# RN821X_RN721X_SOC_V2 register map
File version: v1.0.7
CPU: CM0 r0p0, little endian, no MPU, no FPU, 3 interrupt priority bits
Registers are 32-bit, read-write, reset 0x0 unless marked. A register's access mark holds for its fields unless they carry their own. Offsets are from the block's base; [hi:lo] are bit positions; {n}, {i} and the like mark numbered series; 'fields as' and 'values as' point back to an identical list.

## SYSCTL — system control
Base 0x40034000
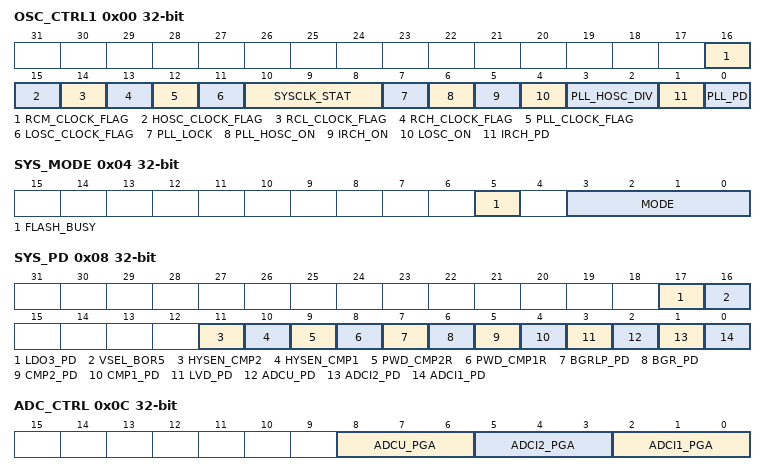
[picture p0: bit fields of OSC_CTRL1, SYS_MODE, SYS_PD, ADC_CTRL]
0x00 OSC_CTRL1 — system oscillator control register No.1
  [16] RCM_CLOCK_FLAG ro — RCM ON status flag
    0=OFF (clock off); 1=ON (clock on)
  [15] HOSC_CLOCK_FLAG ro — HOSC ON status flag
    0=OFF (clock off); 1=ON (clock on)
  [14] RCL_CLOCK_FLAG ro — internal RCL ON status flag
    0=OFF (clock off); 1=ON (clock on)
  [13] RCH_CLOCK_FLAG ro — internal RCH ON status flag
    0=OFF (clock off); 1=ON (clock on)
  [12] PLL_CLOCK_FLAG ro — PLL ON status flag
    0=OFF (clock off); 1=ON (clock on)
  [11] LOSC_CLOCK_FLAG ro — LOSC ON status flag
    0=OFF (clock off); 1=ON (clock on)
  [10:8] SYSCLK_STAT ro — system clock freq status flag
    0=7M4 (current system clock freq = 7.3728MHz); 1=3M6 (current system clock freq = 3.6864MHz); 2=1M8 (current system clock freq = 1.8432MHz); 3=32K (current system clock freq = 32.768KHz); 4=14M7 (current system clock freq = 14.7456Mhz); 5=29M5 (current system clock freq = 29.4912Mhz)
  [7] PLL_LOCK ro — PLL locked flag
    0=NUL (PLL hasn't locked yet); 1=LOCK (PLL locked)
  [6] PLL_HOSC_ON ro — system clock flag of external high-frequence oscillator or internal PLL
    0=NUL (PLL_HOSC isn't used as system clock); 1=SYS_CLK (PLL_HOSC used as system clock)
  [5] IRCH_ON ro — system clock flag of internal RC oscillator
    0=NUL (IRCH isn't used as system clock); 1=SYS_CLK (IRCH used as system clock)
  [4] LOSC_ON ro — system clock flag of losc or RCL
    0=NUL (losc isn't used as system clock); 1=SYS_CLK (losc used as system clock)
  [3:2] PLL_HOSC_DIV — system clock division(applicable for high frequency mode(PLL or HOSC))
    0=DIV1 (when PLL/HOSC selected as system clock not divided); 1=DIV2 (when PLL/HOSC selected as system clock divided by 2); 2=DIV4 (when PLL/HOSC selected as system clock divided by 4); 3=DIV8 (when PLL/HOSC selected as system clock divided by 8)
  [1] IRCH_PD — internal RCH oscillator disable bit (=1 disable, =0 enable)
    1=DIS (disable); 0=EN (enable)
  [0] PLL_PD — PLL disable bit (=1 disable, =0 enable)
    1=DIS (disable); 0=EN (enable)
0x04 SYS_MODE — system mode control register
  [5] FLASH_BUSY ro — FLASH busy status flag (=1 busy, =0 idle)
    0=IDLE; 1=BUSY (idle)
  [3:0] MODE — system clock configuration bits
    13=HCM (select HCM mode as system mode); 14=RCM (select RCM mode as system mode); 15=LCM (select LCM mode as system mode)
0x08 SYS_PD — system power-down control register
  [17] LDO3_PD — LDO3 power down switch bit(=1 power on, =0 power off)
    0=OFF (power off); 1=ON (power on)
  [16] VSEL_BOR5 — BOR5 voltage threshold bit
    0=HIGH (BOR5 high level(2.5/2.2V)); 1=LOW (BOR5 low level(2.1/1.8V))
  [11] HYSEN_CMP2 — CMP2 hysteresis switch bit
    1=ON (switch on); 0=OFF (switch off)
  [10] HYSEN_CMP1 — CMP1 hysteresis switch bit
    1=ON (switch on); 0=OFF (switch off)
  [9] PWD_CMP2R — switch bit of CMP2 internal simpling resistor(=1 register off, =0 register on)
    0=ON (switch on); 1=OFF (switch off)
  [8] PWD_CMP1R — switch bit of CMP1 internal simpling resistor(=1 register off, =0 register on)
    0=ON (switch on); 1=OFF (switch off)
  [7] BGRLP_PD — BGRLP power down switch bit(=1 power down, =0 power on)
    0=ON (power on); 1=OFF (power off)
  [6] BGR_PD — BGR power down switch bit(=1 power down, =0 power on)
    0=ON (power on); 1=OFF (power off)
  [5] CMP2_PD — power down switch bit of Comparator No.2 (=1 power down, =0 power on)
    0=ON (power on); 1=OFF (power off)
  [4] CMP1_PD — power down switch bit of Comparator No.1 (=1 power down, =0 power on)
    0=ON (power on); 1=OFF (power off)
  [3] LVD_PD — LVD power down switch bit(=1 power down, =0 power on)
    0=ON (power on); 1=OFF (power off)
  [2] ADCU_PD — U ADC power down switch bit(=1 power down, =0 power on)
    0=ON (power on); 1=OFF (power off)
  [1] ADCI2_PD — I2 ADC power down switch bit(=1 power down, =0 power on)
    0=ON (power on); 1=OFF (power off)
  [0] ADCI1_PD — I1 ADC power down switch bit(=1 power down, =0 power on)
    0=ON (power on); 1=OFF (power off)
0x0C ADC_CTRL — ADC control register
  [8:6] ADCU_PGA — ADC U PGA config bits
    0=1TIME (PGA config 1 time); 1=2TIME (PGA config 2 times); 2=4TIME (PGA config 4 times)
  [5:3] ADCI2_PGA — ADC I2 PGA config bits
    values as ADCU_PGA
  [2:0] ADCI1_PGA — ADC I1 PGA config bits
    0=1TIME (PGA config 1 time); 1=2TIME (PGA config 2 times); 2=8TIME (PGA config 8 times); 3=16TIME (PGA config 16 times)
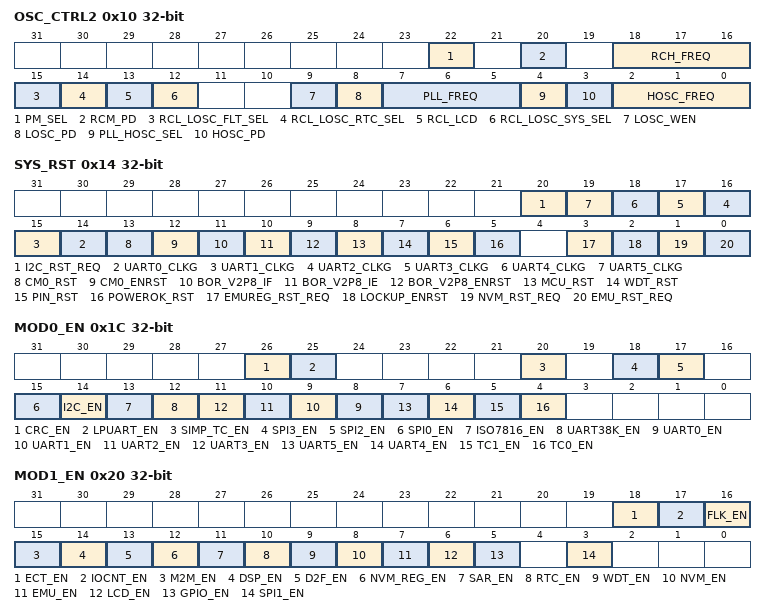
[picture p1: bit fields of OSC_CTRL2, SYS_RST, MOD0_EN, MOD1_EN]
0x10 OSC_CTRL2 — system oscillator control No.2
  [22] PM_SEL — EMU power mode selection bit
    0=NORM (select as normal mode); 1=NVM (select as NVM mode)
  [20] RCM_PD — internal RCM enable bit
    0=OFF (power off); 1=ON (power on)
  [18:16] RCH_FREQ — RCH frequency selection bits
    0=1M8 (internal RCH freq select 1.8432MHz); 1=3M6 (internal RCH freq select 3.6864MHz); 2=7M4 (internal RCH freq select 7.3728MHz); 3=14M7 (internal RCH freq select 14.7456Mhz); 4=29M5 (internal RCH freq select 29.4912Mhz)
  [15] RCL_LOSC_FLT_SEL — clock selection bit (RCL/LOSC) for KBI filter
    0=LOSC (select LOSC); 1=RCL (select RCL)
  [14] RCL_LOSC_RTC_SEL — clock selection bit (RCL/LOSC) for RTC
    0=LOSC (select LOSC); 1=RCL (select RCL)
  [13] RCL_LCD — clock selection bit (RCL/LOSC) for LCD
    0=LOSC (select LOSC); 1=RCL (select RCL)
  [12] RCL_LOSC_SYS_SEL — system clock selection bit for low frequency mode
    0=LOSC (select LOSC); 1=RCL (select RCL)
  [9] LOSC_WEN — LOSC_PD writable enable/disable bit
    0=DIS (LOSC_PD write disable); 1=EN (LOSC_PD write enable)
  [8] LOSC_PD — LOSC power down switch bit
    0=ON (power on); 1=OFF (power off)
  [7:5] PLL_FREQ — PLL freq selection bits
    0=7M4 (PLL freq select 7.3728MHz); 1=14M7 (PLL freq select 14.7456Mhz); 2=29M5 (PLL freq select 29.4912Mhz); 3=59M_DIV2 (PLL freq select 58.9824Mhz divided by 2)
  [4] PLL_HOSC_SEL — system clock selection bits for full speed mode
    0=PLL (select PLL as system clock); 1=HOSC (select HOSC as system clock)
  [3] HOSC_PD — HOSC disable bit (=1 disable HOSC, =0 enable HOSC)
    0=ON (power on); 1=OFF (power off)
  [2:0] HOSC_FREQ — freq of external high-frequence oscillator select bits
    0=7M4 (external high-frequence oscillator freq = 7.3728MHz); 1=14M7 (external high-frequence oscillator freq = 14.7456Mhz); 3=29M5_PLUS (external high-frequence oscillator freq = 29.4912Mhz (driver enhanced))
0x14 SYS_RST — system reset register
  [20] I2C_RST_REQ — I2C module soft reset cfg bit
    1=EN (enable module soft reset); 0=DIS (disable module soft reset)
  [n+14] UART{n}_CLKG (n=0..5) — UART{n} CM0 reset lock enable bit(during CM0 reset period lock transmission between CPU and UART)
  [13] CM0_RST write-1-clears — CM0 reset flag
    1=OCC (reset occured); 0=NUL (reset not occured)
  [12] CM0_ENRST — CM0 reset enable bit(do not reset EMU related module)
  [11] BOR_V2P8_IF write-1-clears — BOR 2.8V threshold interrupt flag
  [10] BOR_V2P8_IE — BOR 2.8V threshold interrupt enable bit
  [9] BOR_V2P8_ENRST — lower than BOR 2.8V threshold reset CPU cfg bit
  [8] MCU_RST write-1-clears — CPU reset flag(software or LOCKUP) (=1 reset occured)
    1=OCC (reset occured); 0=NUL (reset not occured)
  [7] WDT_RST write-1-clears — WDT reset flag (=1 reset occurd)
    1=OCC (reset occured); 0=NUL (reset not occured)
  [6] PIN_RST write-1-clears — external pin reset flag (=1 reet occured)
    1=OCC (reset occured); 0=NUL (reset not occured)
  [5] POWEROK_RST write-1-clears — power-on reset flag (=1 reset ccured)
    1=OCC (reset occured); 0=NUL (reset not occured)
  [3] EMUREG_RST_REQ — EMU/NVM/FLK module soft reset cfg bit
    values as I2C_RST_REQ
  [2] LOCKUP_ENRST — selection for the connection of lockup and system reset
    0=DIS (lock up can not cause system reset); 1=EN (lock up cause system reset)
  [1] NVM_RST_REQ — NVM module soft reset cfg bit
    values as I2C_RST_REQ
  [0] EMU_RST_REQ — EMU module soft reset cfg bit
    values as I2C_RST_REQ
0x18 MAP_CTRL — system control register
  [2:0] REMAP — system remap address configuration bits
    0=FLASH mapped at address 0; 1=FLASH mapped at address 1/2 (2nd FLASH at 0x0, 1st FLASH at 0x4000 and bootload at 0); 2=FLASH switch mapping address with SRAM(FLASH at 0x10000000 and SRAM at 0); 3=BOOTROM mapped at address 0; 4=FLASH mapped at address 1/2 total memory capacity(only support less than 512KB)
0x1C MOD0_EN — module enable register No.0
  [all] fields
    0=DIS (module disabled and clock stop); 1=EN (module enabled and clock start)
  [26] CRC_EN — CRC enable bit
  [25] LPUART_EN — LPUART enable bit
  [20] SIMP_TC_EN — SIMP_TC enable bit
  [18] SPI3_EN — SPI3 enable bit
  [17] SPI2_EN — SPI2 enable bit
  [15] SPI0_EN — SPI0 enable bit
  [14] I2C_EN — I2C enable bit
  [13] ISO7816_EN — ISO7816 enable bit
  [12] UART38K_EN — UART38K enable bit
  [n+8] UART{n}_EN (n=0..3) — UART{n} enable bit
  [7] UART5_EN — UART5 enable bit
  [6] UART4_EN — UART4 enable bit
  [5] TC1_EN — TC1 enable bit
  [4] TC0_EN — TC0 enable bit
0x20 MOD1_EN — module enable register No.1
  [18] ECT_EN — ECT enable bit
    0=DIS (clock stop); 1=EN (clock start)
  [17] IOCNT_EN — IOCNT enable bit
    0=DIS (clock stop); 1=EN (clock start)
  [16] FLK_EN — FLK enable bit
    0=DIS (clock stop); 1=EN (clock start)
  [15] M2M_EN — M2M enable bit
    0=DIS (clock stop); 1=EN (clock start)
  [14] DSP_EN — DSP enable bit
    0=DIS (clock stop); 1=EN (clock start)
  [13] D2F_EN — D2F enable bit
    0=DIS (clock stop); 1=EN (clock start)
  [12] NVM_REG_EN — NVM REG read/write enable bit
    0=DIS (clock stop); 1=EN (clock start)
  [11] SAR_EN — SAR enable bit
    0=DIS (clock stop); 1=EN (clock start)
  [10] RTC_EN — RTC enable bit
    0=DIS (clock stop); 1=EN (clock start)
  [9] WDT_EN — WDT enable bit
    0=DIS (clock stop); 1=EN (clock start)
  [8] NVM_EN — NVM enable bit
    0=DIS (clock stop); 1=EN (clock start)
  [7] EMU_EN — EMU enable bit
    0=DIS (clock stop); 1=EN (clock start)
  [6] LCD_EN — LCD enable bit
    values as the fields of MOD0_EN
  [5] GPIO_EN — GPIO enable bit
    values as the fields of MOD0_EN
  [3] SPI1_EN — SPI1 enable bit
    values as the fields of MOD0_EN
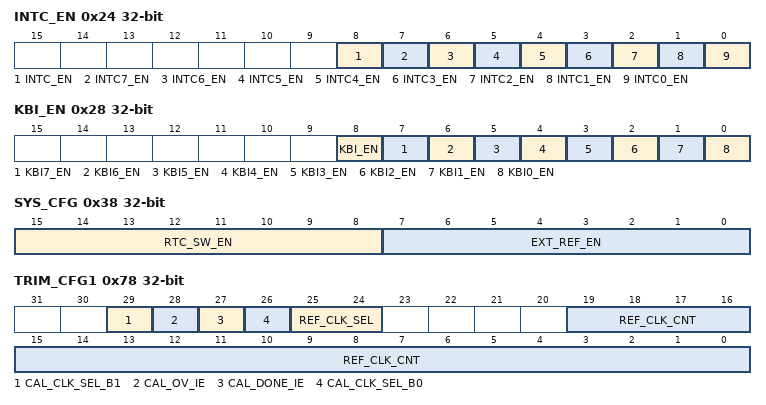
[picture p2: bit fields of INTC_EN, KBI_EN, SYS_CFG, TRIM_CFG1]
0x24 INTC_EN — INTC enable register
  [8] INTC_EN — INTC enable bit
  [7] INTC7_EN — INTC channel No.7 enable bit
  [6] INTC6_EN — INTC channel No.6 enable bit
  [5] INTC5_EN — INTC channel No.5 enable bit
    0=DIS (channel disabled and clock stop); 1=EN (channel enabled and clock start)
  [4] INTC4_EN — INTC channel No.4 enable bit
    values as INTC5_EN
  [3] INTC3_EN — INTC channel No.3 enable bit
    values as INTC5_EN
  [2] INTC2_EN — INTC channel No.2 enable bit
    values as INTC5_EN
  [1] INTC1_EN — INTC channel No.1 enable bit
    values as INTC5_EN
  [0] INTC0_EN — INTC channel No.0 enable bit
    values as INTC5_EN
0x28 KBI_EN — KBI enable register
  [8] KBI_EN — KBI clock enable bit
  [7] KBI7_EN — KBI channel No.7 enable bit
    values as INTC_EN.INTC5_EN
  [6] KBI6_EN — KBI channel No.6 enable bit
    values as INTC_EN.INTC5_EN
  [5] KBI5_EN — KBI channel No.5 enable bit
    values as INTC_EN.INTC5_EN
  [4] KBI4_EN — KBI channel No.4 enable bit
    values as INTC_EN.INTC5_EN
  [3] KBI3_EN — KBI channel No.3 enable bit
    values as INTC_EN.INTC5_EN
  [2] KBI2_EN — KBI channel No.2 enable bit
    values as INTC_EN.INTC5_EN
  [1] KBI1_EN — KBI channel No.1 enable bit
    values as INTC_EN.INTC5_EN
  [0] KBI0_EN — KBI channel No.0 enable bit
    values as INTC_EN.INTC5_EN
0x2C CHIP_ID ro
  [15:0] CHIP_ID
0x30 SYS_PS — system control registers write password register
  [7:0] SYS_PSW — system control register set access protection
    130=PS (SYSCTRL registers offset adderess write access enable); 85=DIS (SYSCTRL registers offset adderess write access disable)
0x34 IRFR_CTRL ro — infra-red modulation clock divisor register
  [5:0] IRFR_CTRL — infra-red modulation clock divisor cfg bits
0x38 SYS_CFG — system configuration register
  [15:8] RTC_SW_EN — RTC clock change enable bits
    117=OFF (RTC clock OFF); 0=ON (RTC clock ON)
  [7:0] EXT_REF_EN — external VREF enable bits
    130=PS (enable external VREF); 0=DIS (disable external VREF)
0x78 TRIM_CFG1 — clock trim configuration register No.1
  [29] CAL_CLK_SEL_B1 — calculated clock selection bit1
  [28] CAL_OV_IE — calculation overflow interrupt enable bit
    0=DIS (disable interrupt); 1=EN (enable interrupt)
  [27] CAL_DONE_IE — calculation down interrupt enable bit
    0=DIS (disable interrupt); 1=EN (enable interrupt)
  [26] CAL_CLK_SEL_B0 — calculated clock selection bit0
  [25:24] REF_CLK_SEL — reference clock selection bits
    0=LOSC (select LOSC as reference clock); 1=HOSC (select HOSC as reference clock); 2=RCH (select RCH as reference clock); 3=PLL (select PLL as reference clock)
  [19:0] REF_CLK_CNT — reference clock counter value bits
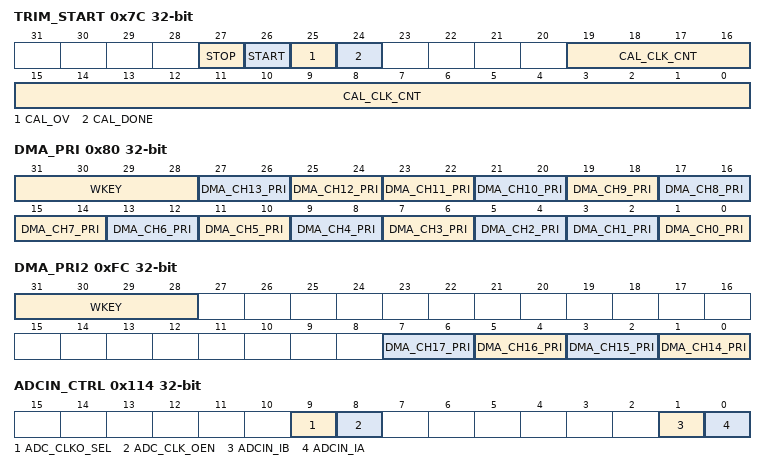
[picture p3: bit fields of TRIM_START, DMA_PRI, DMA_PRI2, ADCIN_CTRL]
0x7C TRIM_START — clock trim start register
  [27] STOP — stop bit of clock trim
    0=NUL (no operation); 1=STOP (stop clock trim(cleared auto while counter down))
  [26] START — start bit of clock trim
    0=NUL (no operation); 1=START (start clock trim(cleared auto while counter down))
  [25] CAL_OV — clock trim counter overflow flag
    0=NUL (clock trim counter not overflow); 1=OV (clock trim counter overflow)
  [24] CAL_DONE — clock trim finish flag
    0=NUL (clock trim not finish); 1=DONE (clock trim finish)
  [19:0] CAL_CLK_CNT ro — counter value of the calculated clock
0x80 DMA_PRI — DMA priority config register
  [31:28] WKEY — write key (0xE)
  [27:26] DMA_CH13_PRI — DMA CH13: TC1 priority setting bits
    3=HIGHEST (DMA highest priority); 2=HIGH (DMA high priority); 1=LOW (DMA low priority); 0=LOWEST (DMA lowest priority)
  [25:24] DMA_CH12_PRI — DMA CH12: CAN priority setting bits
    values as DMA_CH13_PRI
  [2n+1:2n] DMA_CH{n}_PRI (n=6..11) — DMA CH{n}: UART{n-6} priority setting bits
    values as DMA_CH13_PRI
  [2n+1:2n] DMA_CH{n}_PRI (n=2..5) — DMA CH{n}: SPI{n-2} priority setting bits
    values as DMA_CH13_PRI
  [3:2] DMA_CH1_PRI — DMA CH1: EMU priority setting bits
    values as DMA_CH13_PRI
  [1:0] DMA_CH0_PRI — DMA CH0: CACHE priority setting bits
    values as DMA_CH13_PRI
0xF0 FAB_UID0 — chip UID register No.0
  [31:0] FAB_UID0 — chip UID register No.0 bits
0xF4 FAB_UID1 — chip UID register No.1
  [31:0] FAB_UID1 — chip UID register No.1 bits
0xFC DMA_PRI2 — DMA priority config register No.2
  [31:28] WKEY — write key (0xE)
  [7:6] DMA_CH17_PRI — DMA CH17: CPU priority setting bits
    values as DMA_PRI.DMA_CH13_PRI
  [5:4] DMA_CH16_PRI — DMA CH16: M2M priority setting bits
    values as DMA_PRI.DMA_CH13_PRI
  [3:2] DMA_CH15_PRI — DMA CH15: CRC priority setting bits
    values as DMA_PRI.DMA_CH13_PRI
  [1:0] DMA_CH14_PRI — DMA CH14: DSP priority setting bits
    values as DMA_PRI.DMA_CH13_PRI
0x114 ADCIN_CTRL — ADCIN control register
  [9] ADC_CLKO_SEL — ADCIN clock freq selection bit
    0=1M8 (freq select as 1.8432Mhz); 1=3M6 (freq select as 3.6864Mhz)
  [8] ADC_CLK_OEN — ADCIN clock output enable bit
    0=DIS (disable); 1=EN (enble)
  [1] ADCIN_IB — IB channel ADCIN 1bit enable bit
    0=DIS (disable); 1=EN (enble)
  [0] ADCIN_IA — IA channel ADCIN 1bit enable bit
    0=DIS (disable); 1=EN (enble)
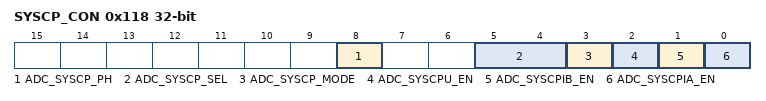
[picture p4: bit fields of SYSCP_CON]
0x118 SYSCP_CON — system chopped wave config register
  [8] ADC_SYSCP_PH — forward and reverse sample cfg bit(only available when adc_syscp_mode=1)
    0=FS (select as forward sampling); 1=RS (select as reverse sampling)
  [5:4] ADC_SYSCP_SEL — forward and reverse sampling freq config bits (only available when adc_syscp_mode=0)
    0=N2048 (N = 2048, period = (1.8432e6/N) Hz); 1=N4096 (N = 4096, period = (1.8432e6/N) Hz); 2=N8192 (N = 8192, period = (1.8432e6/N) Hz); 3=N16384 (N = 16384, period = (1.8432e6/N) Hz)
  [3] ADC_SYSCP_MODE — syschop mode selection bits
    0=AUTO (select as auto mode); 1=MANU (select as manual mode)
  [2] ADC_SYSCPU_EN — U channel syschop enable bit
    0=DIS (disable); 1=EN (enable)
  [1] ADC_SYSCPIB_EN — IB channel syschop enable bit
    0=DIS (disable); 1=EN (enable)
  [0] ADC_SYSCPIA_EN — IA channel syschop enable bit
    0=DIS (disable); 1=EN (enable)
